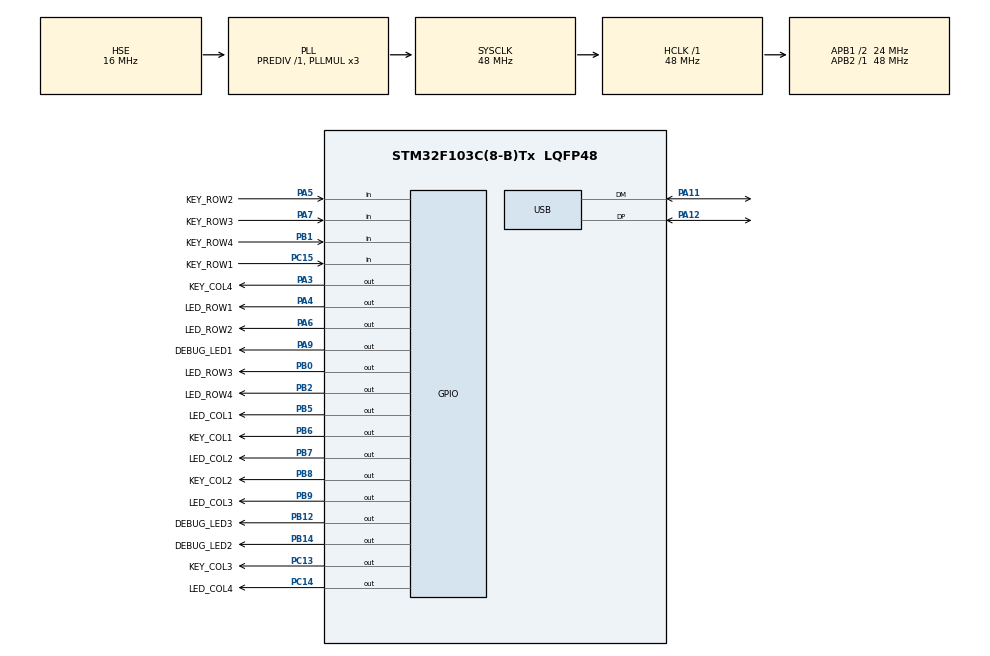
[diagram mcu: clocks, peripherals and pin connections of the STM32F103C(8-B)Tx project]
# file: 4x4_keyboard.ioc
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Mcu.Family=STM32F1
Mcu.Name=STM32F103C(8-B)Tx
Mcu.Package=LQFP48
NVIC.PriorityGroup=NVIC_PRIORITYGROUP_4
NVIC.USB_LP_CAN1_RX0_IRQn=true\:0\:0\:false\:false\:true\:false\:true\:true
PA11.Mode=Device
PA11.Signal=USB_DM
PA12.Mode=Device
PA12.Signal=USB_DP
PA13.Mode=Serial_Wire
PA13.Signal=SYS_JTMS-SWDIO
PA14.Mode=Serial_Wire
PA14.Signal=SYS_JTCK-SWCLK
PA3.GPIO_Label=KEY_COL4
PA3.Signal=GPIO_Output
PA4.GPIO_Label=LED_ROW1
PA4.Signal=GPIO_Output
PA5.GPIO_Label=KEY_ROW2
PA5.Signal=GPIO_Input
PA6.GPIO_Label=LED_ROW2
PA6.Signal=GPIO_Output
PA7.GPIO_Label=KEY_ROW3
PA7.Signal=GPIO_Input
PA9.GPIO_Label=DEBUG_LED1
PA9.Signal=GPIO_Output
PB0.GPIO_Label=LED_ROW3
PB0.Signal=GPIO_Output
PB1.GPIO_Label=KEY_ROW4
PB1.Signal=GPIO_Input
PB12.GPIO_Label=DEBUG_LED3
PB12.Signal=GPIO_Output
PB14.GPIO_Label=DEBUG_LED2
PB14.Signal=GPIO_Output
PB2.GPIO_Label=LED_ROW4
PB2.Signal=GPIO_Output
PB5.GPIO_Label=LED_COL1
PB5.Signal=GPIO_Output
PB6.GPIO_Label=KEY_COL1
PB6.Signal=GPIO_Output
PB7.GPIO_Label=LED_COL2
PB7.Signal=GPIO_Output
PB8.GPIO_Label=KEY_COL2
PB8.Signal=GPIO_Output
PB9.GPIO_Label=LED_COL3
PB9.Signal=GPIO_Output
PC13-TAMPER-RTC.GPIO_Label=KEY_COL3
PC13-TAMPER-RTC.Signal=GPIO_Output
PC14-OSC32_IN.GPIO_Label=LED_COL4
PC14-OSC32_IN.Signal=GPIO_Output
PC15-OSC32_OUT.GPIO_Label=KEY_ROW1
PC15-OSC32_OUT.Signal=GPIO_Input
PD0-OSC_IN.Mode=HSE-External-Oscillator
PD0-OSC_IN.Signal=RCC_OSC_IN
PD1-OSC_OUT.Mode=HSE-External-Oscillator
PD1-OSC_OUT.Signal=RCC_OSC_OUT
ProjectManager.HeapSize=0x200
ProjectManager.StackSize=0x400
ProjectManager.TargetToolchain=STM32CubeIDE
RCC.AHBFreq_Value=48000000
RCC.APB1CLKDivider=RCC_HCLK_DIV2
RCC.APB1Freq_Value=24000000
RCC.APB1TimFreq_Value=48000000
RCC.APB2Freq_Value=48000000
RCC.APB2TimFreq_Value=48000000
RCC.HCLKFreq_Value=48000000
RCC.HSE_VALUE=16000000
RCC.PLLMUL=RCC_PLL_MUL3
RCC.SYSCLKFreq_VALUE=48000000
RCC.SYSCLKSource=RCC_SYSCLKSOURCE_PLLCLK
RCC.USBFreq_Value=48000000
USB_DEVICE.CLASS_NAME_FS=HID
USB_DEVICE.VirtualMode=Hid
USB_DEVICE.VirtualModeFS=Hid_FS
VP_USB_DEVICE_VS_USB_DEVICE_HID_FS.Mode=HID_FS
board=custom

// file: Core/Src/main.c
/* USER CODE BEGIN Header */
/**
  ******************************************************************************
  * @file           : main.c
  * @brief          : Main program body
  ******************************************************************************
  * @attention
  *
  * Copyright (c) 2024 STMicroelectronics.
  * All rights reserved.
  *
  * This software is licensed under terms that can be found in the LICENSE file
  * in the root directory of this software component.
  * If no LICENSE file comes with this software, it is provided AS-IS.
  *
  ******************************************************************************
  */
/* USER CODE END Header */
#include "main.h"
#include "usb_device.h"
#include "gpio.h"

/* USER CODE BEGIN Includes */
#include "app.h"
/* USER CODE END Includes */

void SystemClock_Config(void);

int main(void)
{

  /* MCU Configuration--------------------------------------------------------*/

  /* Reset of all peripherals, Initializes the Flash interface and the Systick. */
  HAL_Init();

  /* Configure the system clock */
  SystemClock_Config();

  /* Initialize all configured peripherals */
  MX_GPIO_Init();
  MX_USB_DEVICE_Init();
  /* USER CODE BEGIN 2 */
  AppInit();
  AppAssignMessages();
  App();
  /* USER CODE END 2 */

  /* Infinite loop */
  while (1)
  {

  }
}

void SystemClock_Config(void)
{
  RCC_OscInitTypeDef RCC_OscInitStruct = {0};
  RCC_ClkInitTypeDef RCC_ClkInitStruct = {0};
  RCC_PeriphCLKInitTypeDef PeriphClkInit = {0};

  /** Initializes the RCC Oscillators according to the specified parameters
  * in the RCC_OscInitTypeDef structure.
  */
  RCC_OscInitStruct.OscillatorType = RCC_OSCILLATORTYPE_HSE;
  RCC_OscInitStruct.HSEState = RCC_HSE_ON;
  RCC_OscInitStruct.HSEPredivValue = RCC_HSE_PREDIV_DIV1;
  RCC_OscInitStruct.HSIState = RCC_HSI_ON;
  RCC_OscInitStruct.PLL.PLLState = RCC_PLL_ON;
  RCC_OscInitStruct.PLL.PLLSource = RCC_PLLSOURCE_HSE;
  RCC_OscInitStruct.PLL.PLLMUL = RCC_PLL_MUL3;
  if (HAL_RCC_OscConfig(&RCC_OscInitStruct) != HAL_OK)
  {
    Error_Handler();
  }

  /** Initializes the CPU, AHB and APB buses clocks
  */
  RCC_ClkInitStruct.ClockType = RCC_CLOCKTYPE_HCLK|RCC_CLOCKTYPE_SYSCLK
                              |RCC_CLOCKTYPE_PCLK1|RCC_CLOCKTYPE_PCLK2;
  RCC_ClkInitStruct.SYSCLKSource = RCC_SYSCLKSOURCE_PLLCLK;
  RCC_ClkInitStruct.AHBCLKDivider = RCC_SYSCLK_DIV1;
  RCC_ClkInitStruct.APB1CLKDivider = RCC_HCLK_DIV2;
  RCC_ClkInitStruct.APB2CLKDivider = RCC_HCLK_DIV1;

  if (HAL_RCC_ClockConfig(&RCC_ClkInitStruct, FLASH_LATENCY_1) != HAL_OK)
  {
    Error_Handler();
  }
  PeriphClkInit.PeriphClockSelection = RCC_PERIPHCLK_USB;
  PeriphClkInit.UsbClockSelection = RCC_USBCLKSOURCE_PLL;
  if (HAL_RCCEx_PeriphCLKConfig(&PeriphClkInit) != HAL_OK)
  {
    Error_Handler();
  }
}

void Error_Handler(void)
{
  __disable_irq();
  while (1)
  {
  }
}
